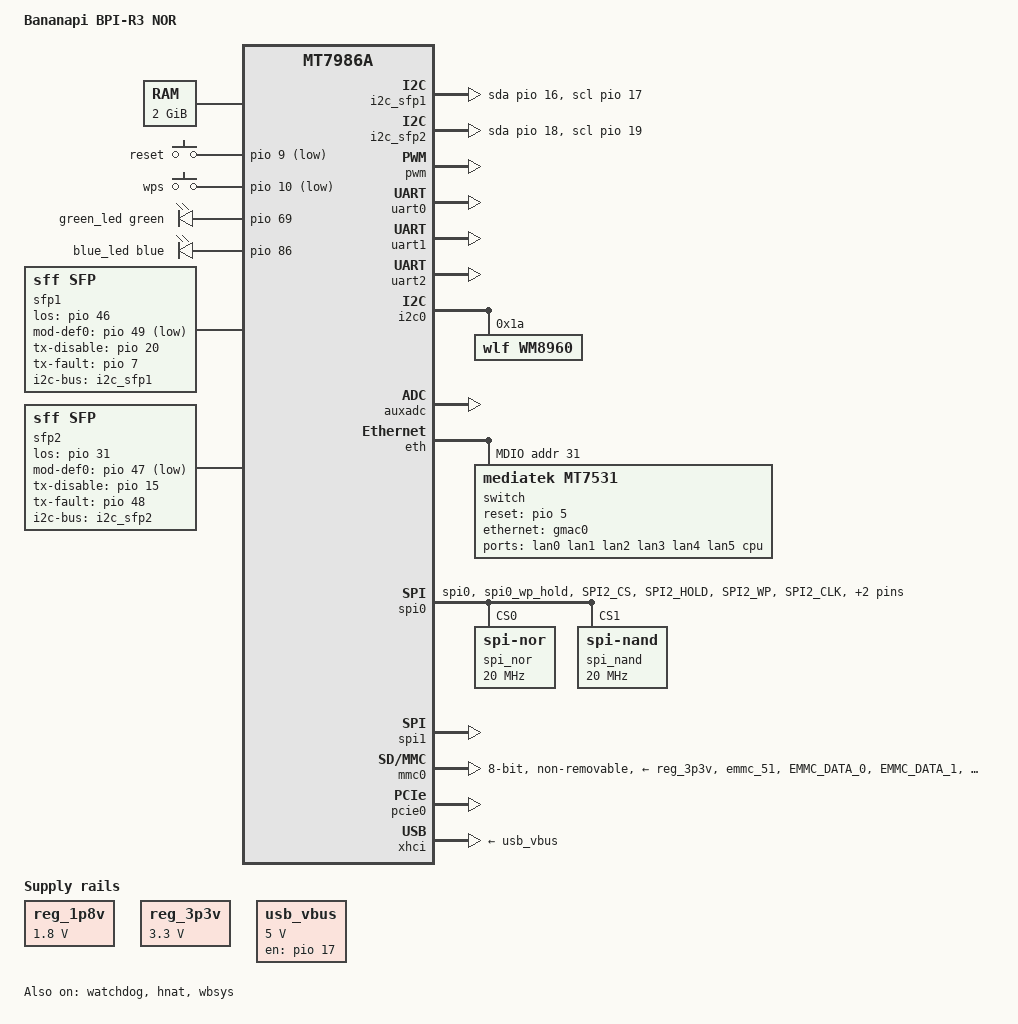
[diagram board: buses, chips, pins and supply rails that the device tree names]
/dts-v1/;
#include "mt7986a.dtsi"
#include "mt7986a-pinctrl.dtsi"
#include <dt-bindings/input/input.h>
#include <dt-bindings/gpio/gpio.h>
#include <dt-bindings/leds/common.h>
#include "mt7986-spim-nor-partition.dtsi"
/ {
	model = "Bananapi BPI-R3 NOR";
	compatible = "bananapi,bpi-r3-nor", "mediatek,mt7986a";
	chosen {
		bootargs = "console=ttyS0,115200n1 loglevel=8  \
				earlycon=uart8250,mmio32,0x11002000";
	};

	memory {
		reg = <0 0x40000000 0 0x80000000>;
	};

	gpio-keys {
		compatible = "gpio-keys";

		reset-key {
			label = "reset";
			linux,code = <KEY_RESTART>;
			gpios = <&pio 9 GPIO_ACTIVE_LOW>;
		};

		wps-key {
			label = "wps";
			linux,code = <KEY_WPS_BUTTON>;
			gpios = <&pio 10 GPIO_ACTIVE_LOW>;
		};
	};

	leds {
		compatible = "gpio-leds";

		green_led: led-0 {
			color = <LED_COLOR_ID_GREEN>;
			function = LED_FUNCTION_POWER;
			gpios = <&pio 69 GPIO_ACTIVE_HIGH>;
			default-state = "on";
		};

		blue_led: led-1 {
			color = <LED_COLOR_ID_BLUE>;
			function = LED_FUNCTION_STATUS;
			gpios = <&pio 86 GPIO_ACTIVE_HIGH>;
			default-state = "off";
		};
	};

	/* i2c of the left SFP cage (wan) */
	i2c_sfp1: i2c-0 {
		compatible = "i2c-gpio";
		sda-gpios = <&pio 16 (GPIO_ACTIVE_HIGH | GPIO_OPEN_DRAIN)>;
		scl-gpios = <&pio 17 (GPIO_ACTIVE_HIGH | GPIO_OPEN_DRAIN)>;
		i2c-gpio,delay-us = <2>;
		#address-cells = <1>;
		#size-cells = <0>;
	};

	/* i2c of the right SFP cage (lan) */
	i2c_sfp2: i2c-1 {
		compatible = "i2c-gpio";
		sda-gpios = <&pio 18 (GPIO_ACTIVE_HIGH | GPIO_OPEN_DRAIN)>;
		scl-gpios = <&pio 19 (GPIO_ACTIVE_HIGH | GPIO_OPEN_DRAIN)>;
		i2c-gpio,delay-us = <2>;
		#address-cells = <1>;
		#size-cells = <0>;
	};

	/* left SFP cage (wan) */
	sfp1: sfp-1 {
		compatible = "sff,sfp";
		i2c-bus = <&i2c_sfp1>;
		los-gpios = <&pio 46 GPIO_ACTIVE_HIGH>;
		maximum-power-milliwatt = <3000>;
		mod-def0-gpios = <&pio 49 GPIO_ACTIVE_LOW>;
		tx-disable-gpios = <&pio 20 GPIO_ACTIVE_HIGH>;
		tx-fault-gpios = <&pio 7 GPIO_ACTIVE_HIGH>;
	};

	/* right SFP cage (lan) */
	sfp2: sfp-2 {
		compatible = "sff,sfp";
		i2c-bus = <&i2c_sfp2>;
		los-gpios = <&pio 31 GPIO_ACTIVE_HIGH>;
		mod-def0-gpios = <&pio 47 GPIO_ACTIVE_LOW>;
		maximum-power-milliwatt = <3000>;
		tx-disable-gpios = <&pio 15 GPIO_ACTIVE_HIGH>;
		tx-fault-gpios = <&pio 48 GPIO_ACTIVE_HIGH>;
	};

	reg_1p8v: regulator-1p8v {
		compatible = "regulator-fixed";
		regulator-name = "fixed-1.8V";
		regulator-min-microvolt = <1800000>;
		regulator-max-microvolt = <1800000>;
		regulator-boot-on;
		regulator-always-on;
	};

	reg_3p3v: regulator-3p3v {
		compatible = "regulator-fixed";
		regulator-name = "fixed-3.3V";
		regulator-min-microvolt = <3300000>;
		regulator-max-microvolt = <3300000>;
		regulator-boot-on;
		regulator-always-on;
	};

	usb_vbus: regulator-usb-vbus {
		compatible = "regulator-fixed";
		regulator-name = "usb_vbus";
		regulator-min-microvolt = <5000000>;
		regulator-max-microvolt = <5000000>;
		gpios = <&pio 17 GPIO_ACTIVE_HIGH>;
		enable-active-high;
		regulator-boot-on;
	};

	sound {
		compatible = "mediatek,mt7986-wm8960-machine";
		mediatek,platform = <&afe>;
		audio-routing = "Headphone", "HP_L",
			"Headphone", "HP_R",
			"LINPUT1", "AMIC",
			"RINPUT1", "AMIC";
		mediatek,audio-codec = <&wm8960>;
		status = "okay";
	};
};

&pwm {
	pinctrl-names = "default";
	pinctrl-0 = <&pwm0_pin &pwm1_pin_g1>;
	status = "okay";
};

&uart0 {
	status = "okay";
};

&uart1 {
	pinctrl-names = "default";
	pinctrl-0 = <&uart1_pins>;
	status = "okay";
};

&uart2 {
	pinctrl-names = "default";
	pinctrl-0 = <&uart2_pins>;
	status = "okay";
};

&i2c0 {
	pinctrl-names = "default";
	pinctrl-0 = <&i2c_pins>;
	status = "okay";

	wm8960: wm8960@1a {
		compatible = "wlf,wm8960";
		reg = <0x1a>;
	};
};

&auxadc {
	status = "okay";
};

&watchdog {
	status = "okay";
};

&eth {
	status = "okay";

	gmac0: mac@0 {
		compatible = "mediatek,eth-mac";
		reg = <0>;
		phy-mode = "2500base-x";

		fixed-link {
			speed = <2500>;
			full-duplex;
			pause;
		};
	};

	gmac1: mac@1 {
		compatible = "mediatek,eth-mac";
		reg = <1>;
		phy-mode = "2500base-x";
		managed = "in-band-status";
		sfp = <&sfp1>;
	};

	mdio: mdio-bus {
		#address-cells = <1>;
		#size-cells = <0>;

		switch@0 {
			compatible = "mediatek,mt7531";
			reg = <31>;
			reset-gpios = <&pio 5 0>;

			ports {
				#address-cells = <1>;
				#size-cells = <0>;

				port@0 {
					reg = <0>;
					label = "lan0";
				};

				port@1 {
					reg = <1>;
					label = "lan1";
				};

				port@2 {
					reg = <2>;
					label = "lan2";
				};

				port@3 {
					reg = <3>;
					label = "lan3";
				};

				port@4 {
					reg = <4>;
					label = "lan4";
				};

				port@5 {
					reg = <5>;
					label = "lan5";
					phy-mode = "2500base-x";
					managed = "in-band-status";
					sfp = <&sfp2>;
				};

				port@6 {
					reg = <6>;
					label = "cpu";
					ethernet = <&gmac0>;
					phy-mode = "2500base-x";

					fixed-link {
						speed = <2500>;
						full-duplex;
						pause;
					};
				};
			};
		};
	};
};

&hnat {
	mtketh-wan = "wan";
	mtketh-lan = "lan";
	mtketh-max-gmac = <2>;
	status = "okay";
};

&spi0 {
	pinctrl-names = "default";
	pinctrl-0 = <&spi_flash_pins>;
	cs-gpios = <0>, <0>;
	status = "okay";

	spi_nor@0 {
		#address-cells = <1>;
		#size-cells = <1>;
		compatible = "jedec,spi-nor";
		reg = <0>;
		spi-max-frequency = <20000000>;
		spi-tx-buswidth = <4>;
		spi-rx-buswidth = <4>;
	};

	spi_nand: spi_nand@1 {
		#address-cells = <1>;
		#size-cells = <1>;
		compatible = "spi-nand";
		reg = <1>;
		spi-max-frequency = <20000000>;
		spi-tx-buswidth = <4>;
		spi-rx-buswidth = <4>;
	};
};

&spi1 {
	pinctrl-names = "default";
	pinctrl-0 = <&spic_pins_g2>;
	status = "okay";
};

&mmc0 {
        pinctrl-names = "default", "state_uhs";
        pinctrl-0 = <&mmc0_pins_default>;
        pinctrl-1 = <&mmc0_pins_uhs>;
        bus-width = <8>;
        max-frequency = <200000000>;
        cap-mmc-highspeed;
        mmc-hs200-1_8v;
        mmc-hs400-1_8v;
        hs400-ds-delay = <0x14014>;
        vmmc-supply = <&reg_3p3v>;
        vqmmc-supply = <&reg_1p8v>;
        non-removable;
        no-sd;
        no-sdio;
        status = "okay";
};

&pcie0 {
	pinctrl-names = "default";
	pinctrl-0 = <&pcie0_pins>;
	status = "okay";
};

&wbsys {
	status = "okay";
	pinctrl-names = "default", "dbdc";
	pinctrl-0 = <&wf_2g_5g_pins>;
	pinctrl-1 = <&wf_dbdc_pins>;
};

&xhci {
 	vusb33-supply = <&reg_3p3v>;
 	vbus-supply = <&usb_vbus>;
 	status = "okay";
};

&pio {
        mmc0_pins_default: mmc0-pins-50-to-61-default {
                mux {
                        function = "flash";
                        groups = "emmc_51";
                };
                conf-cmd-dat {
                        pins = "EMMC_DATA_0", "EMMC_DATA_1", "EMMC_DATA_2",
                               "EMMC_DATA_3", "EMMC_DATA_4", "EMMC_DATA_5",
                               "EMMC_DATA_6", "EMMC_DATA_7", "EMMC_CMD";
                        input-enable;
                        drive-strength = <MTK_DRIVE_4mA>;
                        mediatek,pull-up-adv = <1>;     /* pull-up 10K */
                };
                conf-clk {
                        pins = "EMMC_CK";
                        drive-strength = <MTK_DRIVE_6mA>;
                        mediatek,pull-down-adv = <2>;   /* pull-down 50K */
                };
                conf-ds {
                        pins = "EMMC_DSL";
                        mediatek,pull-down-adv = <2>;   /* pull-down 50K */
                };
                conf-rst {
                        pins = "EMMC_RSTB";
                        drive-strength = <MTK_DRIVE_4mA>;
                        mediatek,pull-up-adv = <1>;     /* pull-up 10K */
                };
        };

        mmc0_pins_uhs: mmc0-pins-50-to-61-uhs {
                mux {
                        function = "flash";
                        groups = "emmc_51";
                };
                conf-cmd-dat {
                        pins = "EMMC_DATA_0", "EMMC_DATA_1", "EMMC_DATA_2",
                               "EMMC_DATA_3", "EMMC_DATA_4", "EMMC_DATA_5",
                               "EMMC_DATA_6", "EMMC_DATA_7", "EMMC_CMD";
                        input-enable;
                        drive-strength = <MTK_DRIVE_4mA>;
                        mediatek,pull-up-adv = <1>;     /* pull-up 10K */
                };
                conf-clk {
                        pins = "EMMC_CK";
                        drive-strength = <MTK_DRIVE_6mA>;
                        mediatek,pull-down-adv = <2>;   /* pull-down 50K */
                };
                conf-ds {
                        pins = "EMMC_DSL";
                        mediatek,pull-down-adv = <2>;   /* pull-down 50K */
                };
                conf-rst {
                        pins = "EMMC_RSTB";
                        drive-strength = <MTK_DRIVE_4mA>;
                        mediatek,pull-up-adv = <1>;     /* pull-up 10K */
                };
        };

	spi_flash_pins: spi-flash-pins-33-to-38 {
		mux {
			function = "flash";
			groups = "spi0", "spi0_wp_hold";
		};
		conf-pu {
			pins = "SPI2_CS", "SPI2_HOLD", "SPI2_WP";
			drive-strength = <MTK_DRIVE_8mA>;
			mediatek,pull-up-adv = <0>;	/* bias-disable */
		};
		conf-pd {
			pins = "SPI2_CLK", "SPI2_MOSI", "SPI2_MISO";
			drive-strength = <MTK_DRIVE_8mA>;
			mediatek,pull-down-adv = <0>;	/* bias-disable */
		};
	};

	wf_2g_5g_pins: wf_2g_5g-pins {
		mux {
			function = "wifi";
			groups = "wf_2g", "wf_5g";
		};
		conf {
			pins = "WF0_HB1", "WF0_HB2", "WF0_HB3", "WF0_HB4",
			       "WF0_HB0", "WF0_HB0_B", "WF0_HB5", "WF0_HB6",
			       "WF0_HB7", "WF0_HB8", "WF0_HB9", "WF0_HB10",
			       "WF0_TOP_CLK", "WF0_TOP_DATA", "WF1_HB1",
			       "WF1_HB2", "WF1_HB3", "WF1_HB4", "WF1_HB0",
			       "WF1_HB5", "WF1_HB6", "WF1_HB7", "WF1_HB8",
			       "WF1_TOP_CLK", "WF1_TOP_DATA";
			drive-strength = <MTK_DRIVE_4mA>;
		};
	};

	wf_dbdc_pins: wf_dbdc-pins {
		mux {
			function = "wifi";
			groups = "wf_dbdc";
		};
		conf {
			pins = "WF0_HB1", "WF0_HB2", "WF0_HB3", "WF0_HB4",
			       "WF0_HB0", "WF0_HB0_B", "WF0_HB5", "WF0_HB6",
			       "WF0_HB7", "WF0_HB8", "WF0_HB9", "WF0_HB10",
			       "WF0_TOP_CLK", "WF0_TOP_DATA", "WF1_HB1",
			       "WF1_HB2", "WF1_HB3", "WF1_HB4", "WF1_HB0",
			       "WF1_HB5", "WF1_HB6", "WF1_HB7", "WF1_HB8",
			       "WF1_TOP_CLK", "WF1_TOP_DATA";
			drive-strength = <MTK_DRIVE_4mA>;
		};
	};
};
